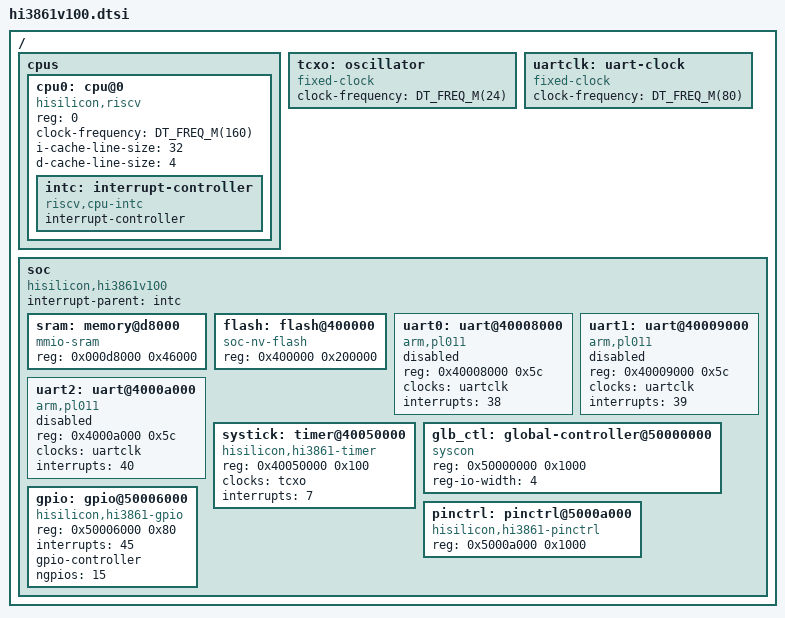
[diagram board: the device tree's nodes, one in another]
/*
 * Copyright (c) 2023 Chen Xingyu <hi@xingrz.me>
 * SPDX-License-Identifier: Apache-2.0
 */

#include <mem.h>
#include <freq.h>

/ {
	cpus {
		#address-cells = <1>;
		#size-cells = <0>;

		cpu0: cpu@0 {
			compatible = "hisilicon,riscv";
			reg = <0>;
			clock-frequency = <DT_FREQ_M(160)>;
			i-cache-line-size = <32>;
			d-cache-line-size = <4>;

			intc: interrupt-controller {
				compatible = "riscv,cpu-intc";
				interrupt-controller;
				#address-cells = <1>;
				#interrupt-cells = <1>;
			};
		};
	};

	tcxo: oscillator {
		compatible = "fixed-clock";
		clock-frequency = <DT_FREQ_M(24)>;
		#clock-cells = <0>;
	};

	uartclk: uart-clock {
		compatible = "fixed-clock";
		clock-frequency = <DT_FREQ_M(80)>;
		#clock-cells = <0>;
	};

	soc {
		compatible = "hisilicon,hi3861v100", "simple-bus";
		interrupt-parent = <&intc>;
		#address-cells = <1>;
		#size-cells = <1>;
		ranges;

		sram: memory@d8000 {
			compatible = "mmio-sram";
			reg = <0x000d8000 0x46000>;
		};

		flash: flash@400000 {
			compatible = "soc-nv-flash";
			reg = <0x400000 0x200000>;
		};

		uart0: uart@40008000 {
			compatible = "arm,pl011";
			reg = <0x40008000 0x5c>;
			clocks = <&uartclk>;
			interrupts = <38>;
			interrupt-names = "UART_0_IRQ";
			status = "disabled";
		};

		uart1: uart@40009000 {
			compatible = "arm,pl011";
			reg = <0x40009000 0x5c>;
			clocks = <&uartclk>;
			interrupts = <39>;
			interrupt-names = "UART_1_IRQ";
			status = "disabled";
		};

		uart2: uart@4000a000 {
			compatible = "arm,pl011";
			reg = <0x4000a000 0x5c>;
			clocks = <&uartclk>;
			interrupts = <40>;
			interrupt-names = "UART_2_IRQ";
			status = "disabled";
		};

		systick: timer@40050000 {
			compatible = "hisilicon,hi3861-timer";
			reg = <0x40050000 0x100>;
			clocks = <&tcxo>;
			interrupts = <7>;
			interrupt-names = "MACHINE_TIMER_IRQ";
		};

		glb_ctl: global-controller@50000000 {
			compatible = "syscon";
			reg = <0x50000000 0x1000>;
			reg-io-width = <4>;
		};

		gpio: gpio@50006000 {
			compatible = "hisilicon,hi3861-gpio";
			reg = <0x50006000 0x80>;
			interrupts = <45>;
			interrupt-names = "GPIO_IRQ";
			gpio-controller;
			#gpio-cells = <2>;
			ngpios = <15>;
		};

		pinctrl: pinctrl@5000a000 {
			compatible = "hisilicon,hi3861-pinctrl";
			reg = <0x5000a000 0x1000>;
		};
	};
};
